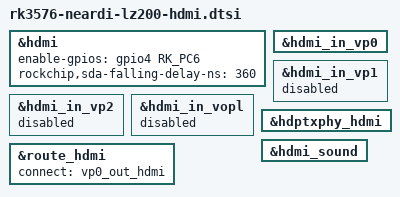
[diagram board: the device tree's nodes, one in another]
/* hdmi */
&hdmi {
	status = "okay";
	enable-gpios = <&gpio4 RK_PC6 GPIO_ACTIVE_HIGH>;
	rockchip,sda-falling-delay-ns = <360>;
};

&hdmi_in_vp0 {
	status = "okay";
};

&hdmi_in_vp1 {
	status = "disabled";
};

&hdmi_in_vp2 {
	status = "disabled";
};

&hdmi_in_vopl {
	status = "disabled";
};

&hdptxphy_hdmi {
	status = "okay";
};

&route_hdmi {
	status = "okay";
	connect = <&vp0_out_hdmi>;
};

&hdmi_sound {
    status = "okay";
};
